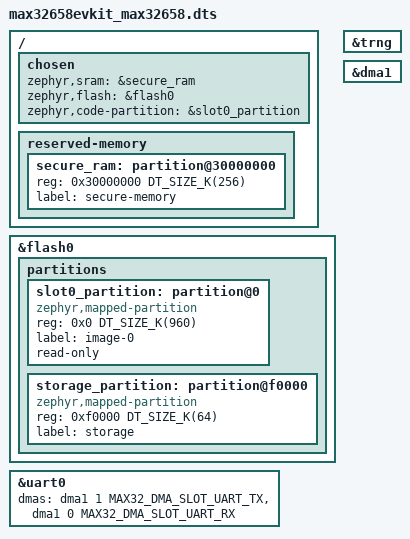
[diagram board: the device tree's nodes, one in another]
/*
 * Copyright (c) 2024-2026 Analog Devices, Inc.
 *
 * SPDX-License-Identifier: Apache-2.0
 */

/dts-v1/;

#include <adi/max32/max32657.dtsi>
#include "max32658evkit_max32658_common.dtsi"

/ {
	chosen {
		zephyr,sram = &secure_ram;
		zephyr,flash = &flash0;
		zephyr,code-partition = &slot0_partition;
	};

	reserved-memory {
		ranges;
		#address-cells = <1>;
		#size-cells = <1>;

		secure_ram: partition@30000000 {
			reg = <0x30000000 DT_SIZE_K(256)>;
			label = "secure-memory";
		};
	};
};

&flash0 {
	partitions {
		ranges;
		#address-cells = <1>;
		#size-cells = <1>;

		slot0_partition: partition@0 {
			compatible = "zephyr,mapped-partition";
			reg = <0x0 DT_SIZE_K(960)>;
			label = "image-0";
			read-only;
		};

		storage_partition: partition@f0000 {
			compatible = "zephyr,mapped-partition";
			reg = <0xf0000 DT_SIZE_K(64)>;
			label = "storage";
		};
	};
};

&trng {
	status = "okay";
};

&uart0 {
	dmas = <&dma1 1 MAX32_DMA_SLOT_UART_TX>, <&dma1 0 MAX32_DMA_SLOT_UART_RX>;
	dma-names = "tx", "rx";
};

&dma1 {
	status = "okay";
};
